# BL808 register map
File version: 0.1
Registers are access not given, no defined reset value unless marked. A register's access mark holds for its fields unless they carry their own. Offsets are from the block's base; [hi:lo] are bit positions.

## OSD_A_DRAW_LAYER_H
Base 0x30013504
Same registers: OSD_DP_DRAW_LAYER_H 0x30015504
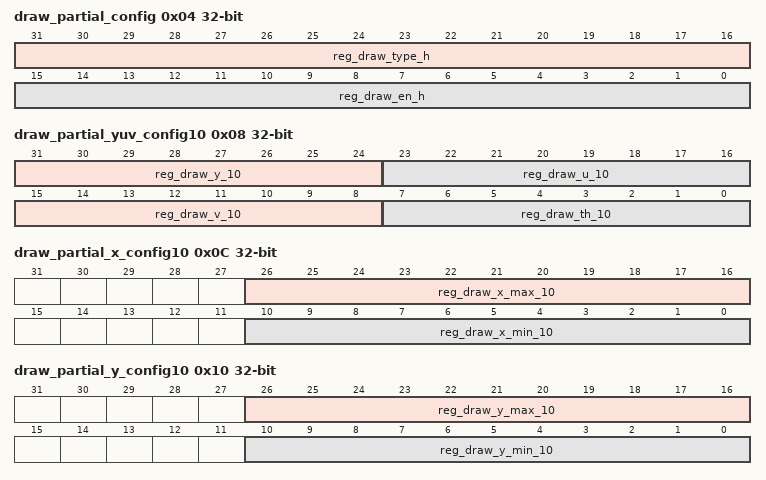
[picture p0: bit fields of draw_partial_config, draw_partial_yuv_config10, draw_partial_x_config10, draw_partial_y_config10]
0x04 draw_partial_config rw
  [31:16] reg_draw_type_h, [15:0] reg_draw_en_h
0x08 draw_partial_yuv_config10 rw
  [31:24] reg_draw_y_10, [23:16] reg_draw_u_10, [15:8] reg_draw_v_10, [7:0] reg_draw_th_10
0x0C draw_partial_x_config10
  [26:16] reg_draw_x_max_10 rw, [10:0] reg_draw_x_min_10 rw
0x10 draw_partial_y_config10
  [26:16] reg_draw_y_max_10 rw, [10:0] reg_draw_y_min_10 rw
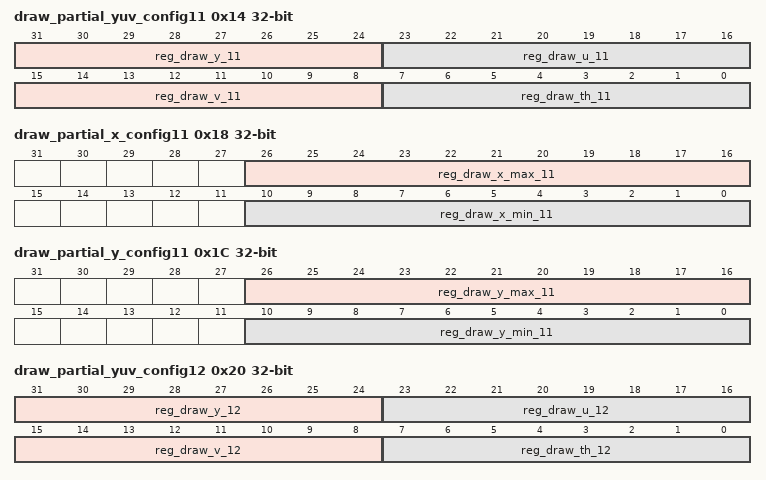
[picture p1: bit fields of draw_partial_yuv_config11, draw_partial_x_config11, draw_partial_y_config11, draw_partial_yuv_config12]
0x14 draw_partial_yuv_config11 rw
  [31:24] reg_draw_y_11, [23:16] reg_draw_u_11, [15:8] reg_draw_v_11, [7:0] reg_draw_th_11
0x18 draw_partial_x_config11
  [26:16] reg_draw_x_max_11 rw, [10:0] reg_draw_x_min_11 rw
0x1C draw_partial_y_config11
  [26:16] reg_draw_y_max_11 rw, [10:0] reg_draw_y_min_11 rw
0x20 draw_partial_yuv_config12 rw
  [31:24] reg_draw_y_12, [23:16] reg_draw_u_12, [15:8] reg_draw_v_12, [7:0] reg_draw_th_12
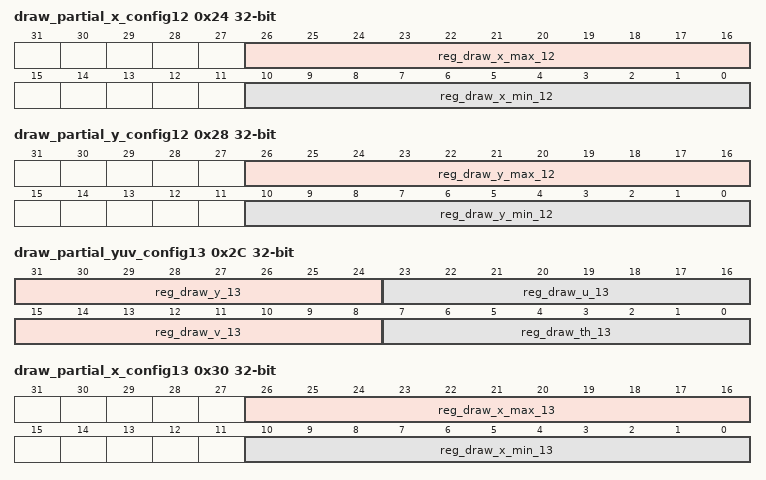
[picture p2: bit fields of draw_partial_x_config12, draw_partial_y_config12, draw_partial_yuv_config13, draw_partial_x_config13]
0x24 draw_partial_x_config12
  [26:16] reg_draw_x_max_12 rw, [10:0] reg_draw_x_min_12 rw
0x28 draw_partial_y_config12
  [26:16] reg_draw_y_max_12 rw, [10:0] reg_draw_y_min_12 rw
0x2C draw_partial_yuv_config13 rw
  [31:24] reg_draw_y_13, [23:16] reg_draw_u_13, [15:8] reg_draw_v_13, [7:0] reg_draw_th_13
0x30 draw_partial_x_config13
  [26:16] reg_draw_x_max_13 rw, [10:0] reg_draw_x_min_13 rw
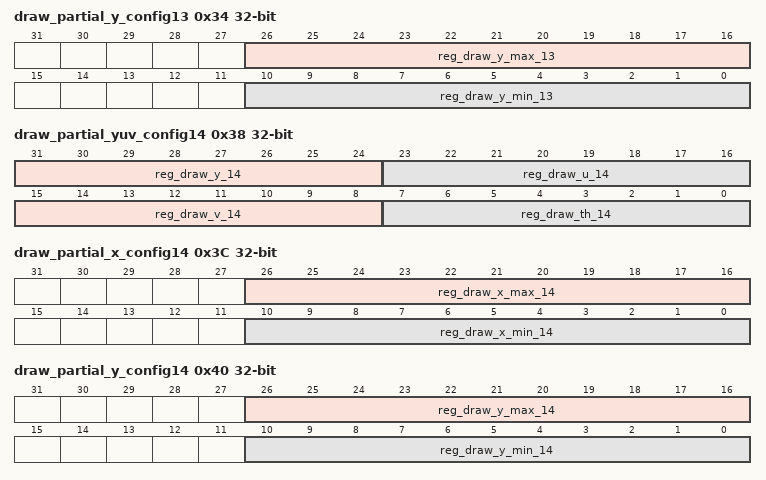
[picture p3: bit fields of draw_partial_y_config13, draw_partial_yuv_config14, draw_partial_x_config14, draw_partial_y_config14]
0x34 draw_partial_y_config13
  [26:16] reg_draw_y_max_13 rw, [10:0] reg_draw_y_min_13 rw
0x38 draw_partial_yuv_config14 rw
  [31:24] reg_draw_y_14, [23:16] reg_draw_u_14, [15:8] reg_draw_v_14, [7:0] reg_draw_th_14
0x3C draw_partial_x_config14
  [26:16] reg_draw_x_max_14 rw, [10:0] reg_draw_x_min_14 rw
0x40 draw_partial_y_config14
  [26:16] reg_draw_y_max_14 rw, [10:0] reg_draw_y_min_14 rw
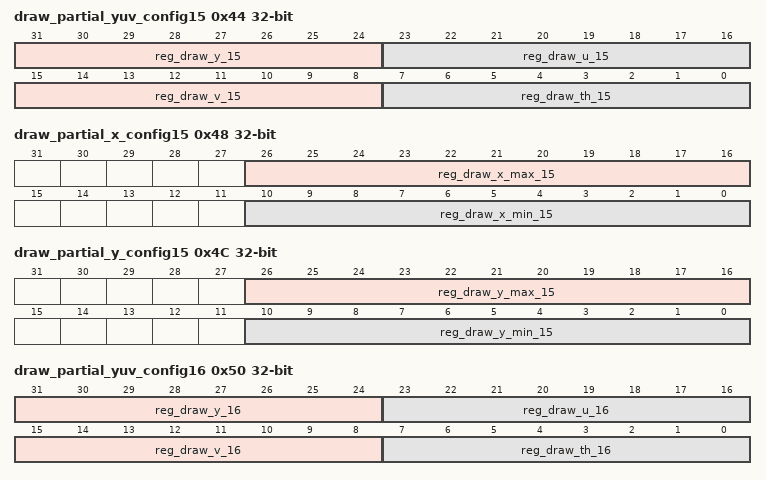
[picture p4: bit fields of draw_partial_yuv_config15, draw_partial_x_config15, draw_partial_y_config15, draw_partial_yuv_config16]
0x44 draw_partial_yuv_config15 rw
  [31:24] reg_draw_y_15, [23:16] reg_draw_u_15, [15:8] reg_draw_v_15, [7:0] reg_draw_th_15
0x48 draw_partial_x_config15
  [26:16] reg_draw_x_max_15 rw, [10:0] reg_draw_x_min_15 rw
0x4C draw_partial_y_config15
  [26:16] reg_draw_y_max_15 rw, [10:0] reg_draw_y_min_15 rw
0x50 draw_partial_yuv_config16 rw
  [31:24] reg_draw_y_16, [23:16] reg_draw_u_16, [15:8] reg_draw_v_16, [7:0] reg_draw_th_16
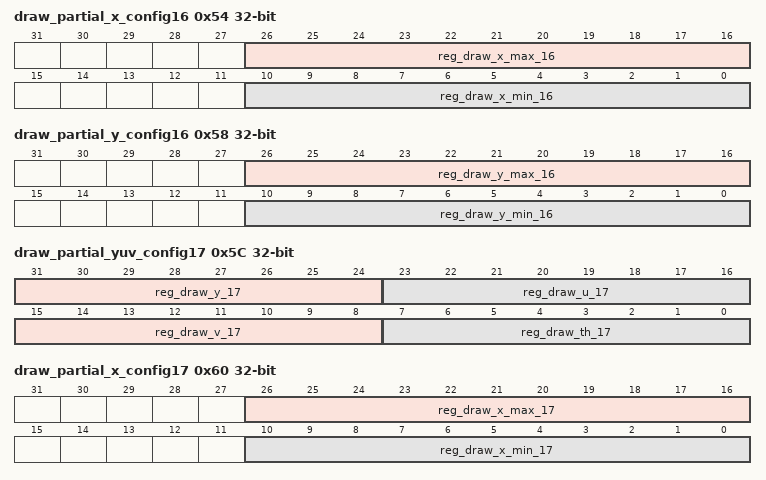
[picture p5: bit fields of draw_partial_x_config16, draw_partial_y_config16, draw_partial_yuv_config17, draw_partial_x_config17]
0x54 draw_partial_x_config16
  [26:16] reg_draw_x_max_16 rw, [10:0] reg_draw_x_min_16 rw
0x58 draw_partial_y_config16
  [26:16] reg_draw_y_max_16 rw, [10:0] reg_draw_y_min_16 rw
0x5C draw_partial_yuv_config17 rw
  [31:24] reg_draw_y_17, [23:16] reg_draw_u_17, [15:8] reg_draw_v_17, [7:0] reg_draw_th_17
0x60 draw_partial_x_config17
  [26:16] reg_draw_x_max_17 rw, [10:0] reg_draw_x_min_17 rw
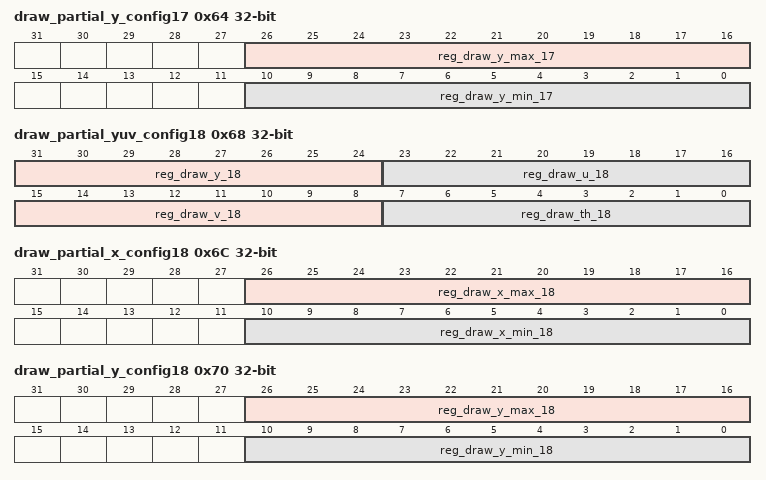
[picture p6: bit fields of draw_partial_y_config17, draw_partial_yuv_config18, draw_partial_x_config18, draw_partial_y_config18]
0x64 draw_partial_y_config17
  [26:16] reg_draw_y_max_17 rw, [10:0] reg_draw_y_min_17 rw
0x68 draw_partial_yuv_config18 rw
  [31:24] reg_draw_y_18, [23:16] reg_draw_u_18, [15:8] reg_draw_v_18, [7:0] reg_draw_th_18
0x6C draw_partial_x_config18
  [26:16] reg_draw_x_max_18 rw, [10:0] reg_draw_x_min_18 rw
0x70 draw_partial_y_config18
  [26:16] reg_draw_y_max_18 rw, [10:0] reg_draw_y_min_18 rw
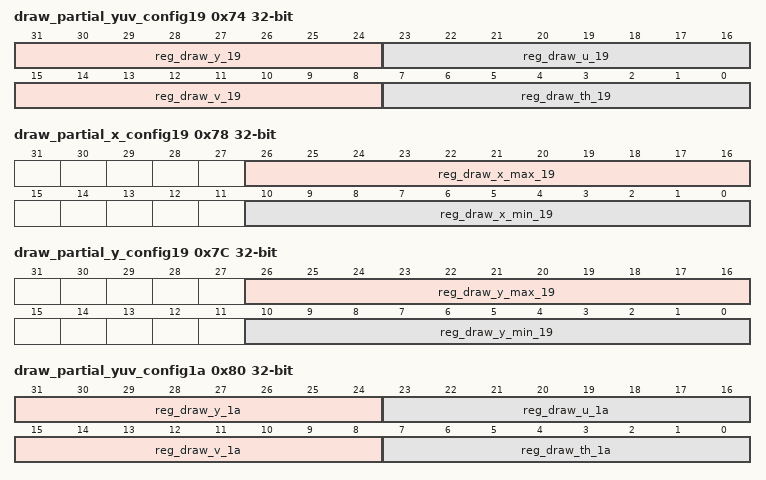
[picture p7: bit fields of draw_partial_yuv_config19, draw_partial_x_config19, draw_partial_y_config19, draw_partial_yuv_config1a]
0x74 draw_partial_yuv_config19 rw
  [31:24] reg_draw_y_19, [23:16] reg_draw_u_19, [15:8] reg_draw_v_19, [7:0] reg_draw_th_19
0x78 draw_partial_x_config19
  [26:16] reg_draw_x_max_19 rw, [10:0] reg_draw_x_min_19 rw
0x7C draw_partial_y_config19
  [26:16] reg_draw_y_max_19 rw, [10:0] reg_draw_y_min_19 rw
0x80 draw_partial_yuv_config1a rw
  [31:24] reg_draw_y_1a, [23:16] reg_draw_u_1a, [15:8] reg_draw_v_1a, [7:0] reg_draw_th_1a
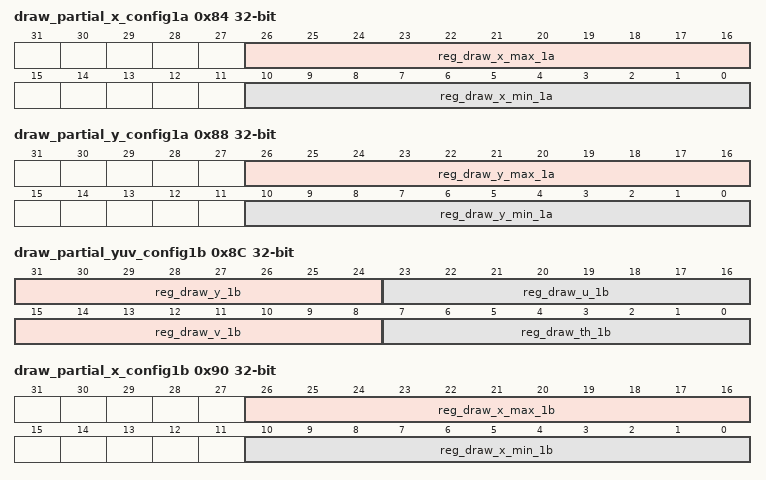
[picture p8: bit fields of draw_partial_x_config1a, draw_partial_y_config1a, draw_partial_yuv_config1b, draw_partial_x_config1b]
0x84 draw_partial_x_config1a
  [26:16] reg_draw_x_max_1a rw, [10:0] reg_draw_x_min_1a rw
0x88 draw_partial_y_config1a
  [26:16] reg_draw_y_max_1a rw, [10:0] reg_draw_y_min_1a rw
0x8C draw_partial_yuv_config1b rw
  [31:24] reg_draw_y_1b, [23:16] reg_draw_u_1b, [15:8] reg_draw_v_1b, [7:0] reg_draw_th_1b
0x90 draw_partial_x_config1b
  [26:16] reg_draw_x_max_1b rw, [10:0] reg_draw_x_min_1b rw
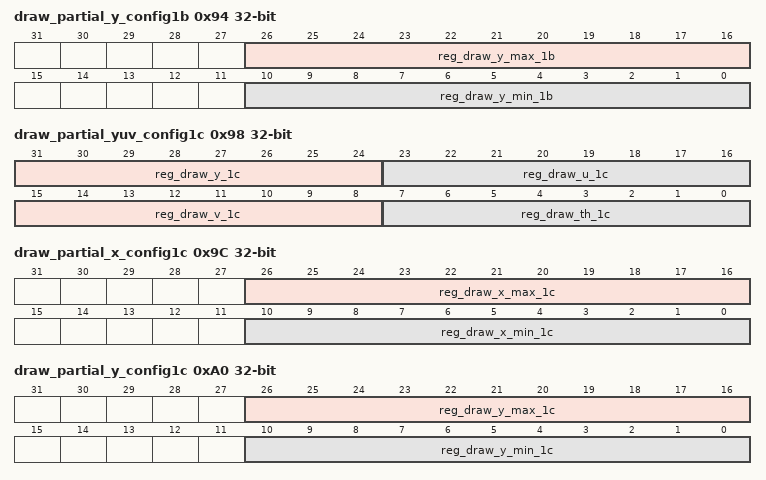
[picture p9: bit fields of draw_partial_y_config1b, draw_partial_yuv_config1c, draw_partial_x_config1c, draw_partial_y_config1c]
0x94 draw_partial_y_config1b
  [26:16] reg_draw_y_max_1b rw, [10:0] reg_draw_y_min_1b rw
0x98 draw_partial_yuv_config1c rw
  [31:24] reg_draw_y_1c, [23:16] reg_draw_u_1c, [15:8] reg_draw_v_1c, [7:0] reg_draw_th_1c
0x9C draw_partial_x_config1c
  [26:16] reg_draw_x_max_1c rw, [10:0] reg_draw_x_min_1c rw
0xA0 draw_partial_y_config1c
  [26:16] reg_draw_y_max_1c rw, [10:0] reg_draw_y_min_1c rw
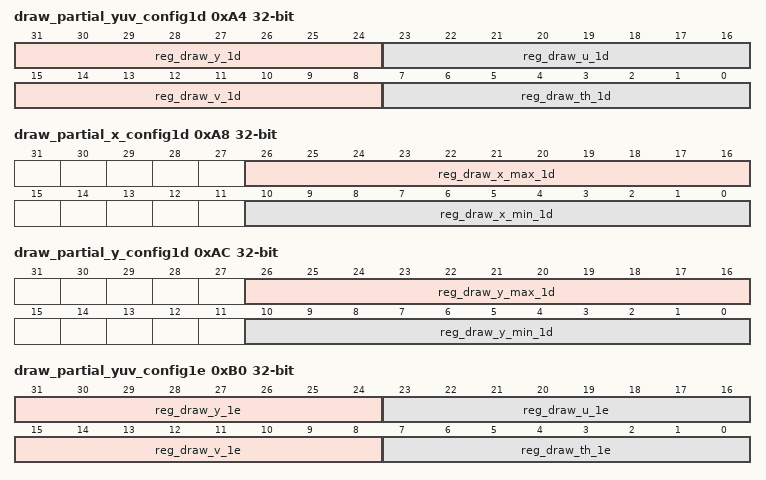
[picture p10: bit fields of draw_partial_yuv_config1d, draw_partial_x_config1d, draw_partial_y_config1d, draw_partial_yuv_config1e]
0xA4 draw_partial_yuv_config1d rw
  [31:24] reg_draw_y_1d, [23:16] reg_draw_u_1d, [15:8] reg_draw_v_1d, [7:0] reg_draw_th_1d
0xA8 draw_partial_x_config1d
  [26:16] reg_draw_x_max_1d rw, [10:0] reg_draw_x_min_1d rw
0xAC draw_partial_y_config1d
  [26:16] reg_draw_y_max_1d rw, [10:0] reg_draw_y_min_1d rw
0xB0 draw_partial_yuv_config1e rw
  [31:24] reg_draw_y_1e, [23:16] reg_draw_u_1e, [15:8] reg_draw_v_1e, [7:0] reg_draw_th_1e
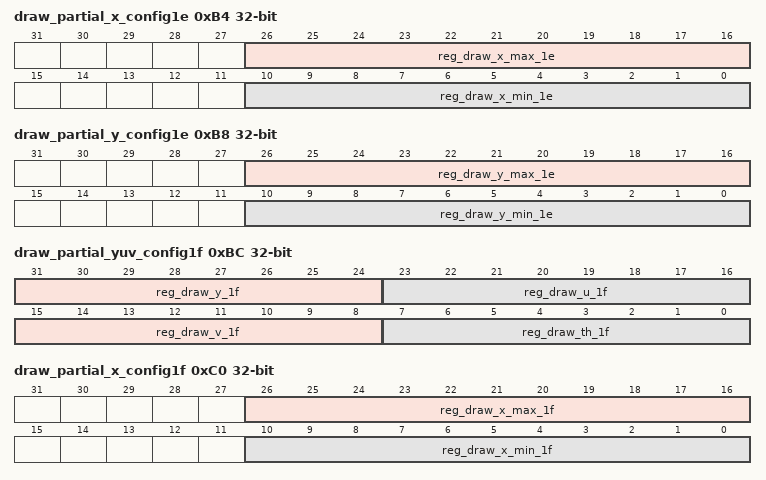
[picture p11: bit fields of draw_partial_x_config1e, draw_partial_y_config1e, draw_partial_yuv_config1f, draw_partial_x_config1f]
0xB4 draw_partial_x_config1e
  [26:16] reg_draw_x_max_1e rw, [10:0] reg_draw_x_min_1e rw
0xB8 draw_partial_y_config1e
  [26:16] reg_draw_y_max_1e rw, [10:0] reg_draw_y_min_1e rw
0xBC draw_partial_yuv_config1f rw
  [31:24] reg_draw_y_1f, [23:16] reg_draw_u_1f, [15:8] reg_draw_v_1f, [7:0] reg_draw_th_1f
0xC0 draw_partial_x_config1f
  [26:16] reg_draw_x_max_1f rw, [10:0] reg_draw_x_min_1f rw
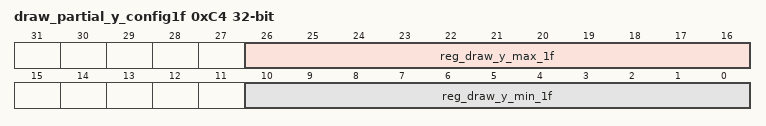
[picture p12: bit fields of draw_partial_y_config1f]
0xC4 draw_partial_y_config1f
  [26:16] reg_draw_y_max_1f rw, [10:0] reg_draw_y_min_1f rw
